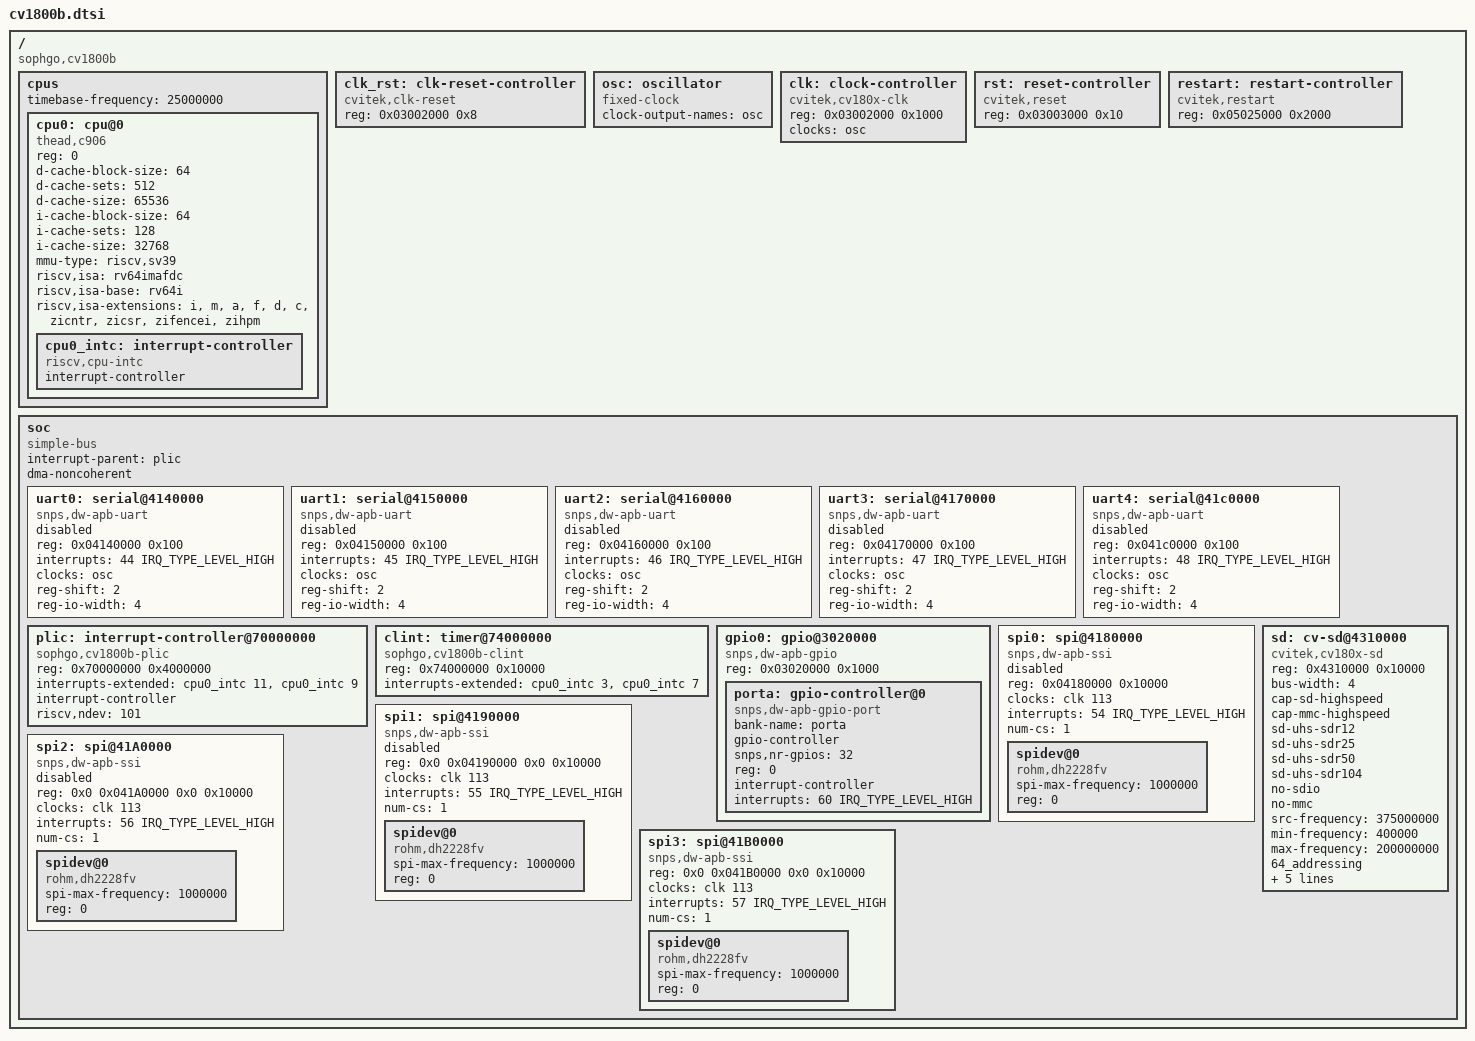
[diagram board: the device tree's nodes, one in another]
// SPDX-License-Identifier: (GPL-2.0 OR MIT)
/*
 * Copyright (C) 2023 Jisheng Zhang <jszhang@kernel.org>
 */

#include <dt-bindings/interrupt-controller/irq.h>
#include <dt-bindings/gpio/gpio.h>

/ {
	compatible = "sophgo,cv1800b";
	#address-cells = <1>;
	#size-cells = <1>;

	cpus: cpus {
		#address-cells = <1>;
		#size-cells = <0>;
		timebase-frequency = <25000000>;

		cpu0: cpu@0 {
			compatible = "thead,c906", "riscv";
			device_type = "cpu";
			reg = <0>;
			d-cache-block-size = <64>;
			d-cache-sets = <512>;
			d-cache-size = <65536>;
			i-cache-block-size = <64>;
			i-cache-sets = <128>;
			i-cache-size = <32768>;
			mmu-type = "riscv,sv39";
			riscv,isa = "rv64imafdc";
			riscv,isa-base = "rv64i";
			riscv,isa-extensions = "i", "m", "a", "f", "d", "c", "zicntr", "zicsr",
					       "zifencei", "zihpm";

			cpu0_intc: interrupt-controller {
				compatible = "riscv,cpu-intc";
				interrupt-controller;
				#address-cells = <0>;
				#interrupt-cells = <1>;
			};
		};
	};

	clk_rst: clk-reset-controller {
		#reset-cells = <1>;
		compatible = "cvitek,clk-reset";
		reg = <0x03002000 0x8>;
	};

	osc: oscillator {
		compatible = "fixed-clock";
		clock-output-names = "osc";
		#clock-cells = <0>;
	};

	clk: clock-controller {
		compatible = "cvitek,cv180x-clk";
		reg = <0x03002000 0x1000>;
		clocks = <&osc>;
		#clock-cells = <1>;
	};

	rst: reset-controller {
		#reset-cells = <1>;
		compatible = "cvitek,reset";
		reg = <0x03003000 0x10>;
	};

	restart: restart-controller {
		compatible = "cvitek,restart";
		reg = <0x05025000 0x2000>;
	};

	soc {
		compatible = "simple-bus";
		interrupt-parent = <&plic>;
		#address-cells = <1>;
		#size-cells = <1>;
		dma-noncoherent;
		ranges;

		uart0: serial@4140000 {
			compatible = "snps,dw-apb-uart";
			reg = <0x04140000 0x100>;
			interrupts = <44 IRQ_TYPE_LEVEL_HIGH>;
			clocks = <&osc>;
			reg-shift = <2>;
			reg-io-width = <4>;
			status = "disabled";
		};

		uart1: serial@4150000 {
			compatible = "snps,dw-apb-uart";
			reg = <0x04150000 0x100>;
			interrupts = <45 IRQ_TYPE_LEVEL_HIGH>;
			clocks = <&osc>;
			reg-shift = <2>;
			reg-io-width = <4>;
			status = "disabled";
		};

		uart2: serial@4160000 {
			compatible = "snps,dw-apb-uart";
			reg = <0x04160000 0x100>;
			interrupts = <46 IRQ_TYPE_LEVEL_HIGH>;
			clocks = <&osc>;
			reg-shift = <2>;
			reg-io-width = <4>;
			status = "disabled";
		};

		uart3: serial@4170000 {
			compatible = "snps,dw-apb-uart";
			reg = <0x04170000 0x100>;
			interrupts = <47 IRQ_TYPE_LEVEL_HIGH>;
			clocks = <&osc>;
			reg-shift = <2>;
			reg-io-width = <4>;
			status = "disabled";
		};

		uart4: serial@41c0000 {
			compatible = "snps,dw-apb-uart";
			reg = <0x041c0000 0x100>;
			interrupts = <48 IRQ_TYPE_LEVEL_HIGH>;
			clocks = <&osc>;
			reg-shift = <2>;
			reg-io-width = <4>;
			status = "disabled";
		};

		plic: interrupt-controller@70000000 {
			compatible = "sophgo,cv1800b-plic", "thead,c900-plic";
			reg = <0x70000000 0x4000000>;
			interrupts-extended = <&cpu0_intc 11>, <&cpu0_intc 9>;
			interrupt-controller;
			#address-cells = <0>;
			#interrupt-cells = <2>;
			riscv,ndev = <101>;
		};

		clint: timer@74000000 {
			compatible = "sophgo,cv1800b-clint", "thead,c900-clint";
			reg = <0x74000000 0x10000>;
			interrupts-extended = <&cpu0_intc 3>, <&cpu0_intc 7>;
		};

		gpio0: gpio@3020000 {
			compatible = "snps,dw-apb-gpio";
			reg = <0x03020000 0x1000>;
			#address-cells = <1>;
			#size-cells = <0>;

			porta: gpio-controller@0 {
				compatible = "snps,dw-apb-gpio-port";
				bank-name = "porta";
				gpio-controller;
				#gpio-cells = <2>;
				snps,nr-gpios = <32>;
				reg = <0>;
				interrupt-controller;
				interrupts = <60 IRQ_TYPE_LEVEL_HIGH>;
			};
		};

		spi0: spi@4180000 {
			compatible = "snps,dw-apb-ssi";
			reg = <0x04180000 0x10000>;
			#address-cells = <1>;
			#size-cells = <0>;
			clocks = <&clk 113>;
			interrupts = <54 IRQ_TYPE_LEVEL_HIGH>;
			status = "disabled";
			num-cs = <1>;
			spidev@0 {
				compatible = "rohm,dh2228fv";
				spi-max-frequency = <1000000>;
				reg = <0>;
			};
		};

		spi1: spi@4190000 {
			compatible = "snps,dw-apb-ssi";
			reg = <0x0 0x04190000 0x0 0x10000>;
			clocks = <&clk 113>;
			#address-cells = <1>;
			#size-cells = <0>;
			interrupts = <55 IRQ_TYPE_LEVEL_HIGH>;
			status = "disabled";
			num-cs = <1>;
			spidev@0 {
				compatible = "rohm,dh2228fv";
				spi-max-frequency = <1000000>;
				reg = <0>;
			};
		};

		spi2: spi@41A0000 {
			compatible = "snps,dw-apb-ssi";
			reg = <0x0 0x041A0000 0x0 0x10000>;
			clocks = <&clk 113>;
			#address-cells = <1>;
			#size-cells = <0>;
			interrupts = <56 IRQ_TYPE_LEVEL_HIGH>;
			status = "disabled";
			num-cs = <1>;
			spidev@0 {
				compatible = "rohm,dh2228fv";
				spi-max-frequency = <1000000>;
				reg = <0>;
			};
		};

		spi3: spi@41B0000 {
			compatible = "snps,dw-apb-ssi";
			reg = <0x0 0x041B0000 0x0 0x10000>;
			clocks = <&clk 113>;
			#address-cells = <1>;
			#size-cells = <0>;
			interrupts = <57 IRQ_TYPE_LEVEL_HIGH>;
			status = "okay";
			num-cs = <1>;
			spidev@0 {
				compatible = "rohm,dh2228fv";
				spi-max-frequency = <1000000>;
				reg = <0>;
			};
		};

		sd: cv-sd@4310000 {
			compatible = "cvitek,cv180x-sd";
			reg = <0x4310000 0x10000>;
			reg-names = "core_mem";
			bus-width = <4>;
			cap-sd-highspeed;
			cap-mmc-highspeed;
			sd-uhs-sdr12;
			sd-uhs-sdr25;
			sd-uhs-sdr50;
			sd-uhs-sdr104;
			no-sdio;
			no-mmc;
			/*no-1-8-v;*/
			src-frequency = <375000000>;
			min-frequency = <400000>;
			max-frequency = <200000000>;
			64_addressing;
			reset_tx_rx_phy;
			reset-names = "sdhci";
			pll_index = <0x6>;
			pll_reg = <0x3002070>;
			cvi-cd-gpios = <&porta 13 GPIO_ACTIVE_LOW>;
			interrupts = <36 IRQ_TYPE_LEVEL_HIGH>;
		};

	};
};
